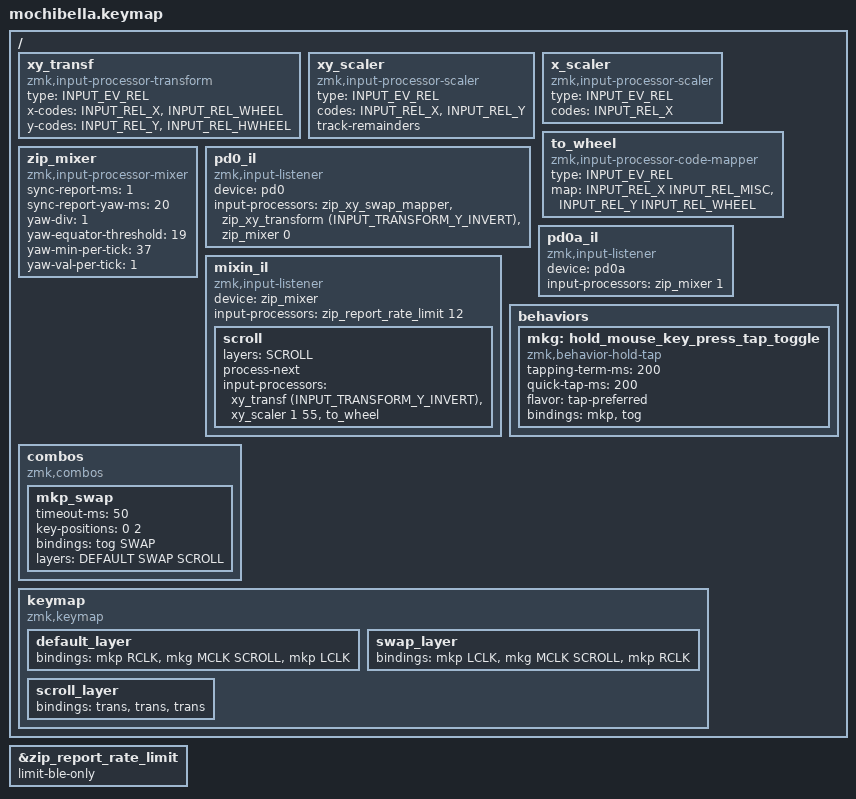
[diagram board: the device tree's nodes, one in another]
/*
 * Copyright (c) 2020 The ZMK Contributors
 *
 * SPDX-License-Identifier: MIT
 */

#include <zephyr/dt-bindings/input/input-event-codes.h>

#include <behaviors.dtsi>
// #include <behaviors/mouse_keys.dtsi>
#include <behaviors/mouse_key_press.dtsi>
#include <behaviors/mouse_key_toggle.dtsi>
#include <dt-bindings/zmk/keys.h>
#include <dt-bindings/zmk/bt.h>
#include <dt-bindings/zmk/outputs.h>
#include <dt-bindings/zmk/mouse.h>
#include <dt-bindings/zmk/input_transform.h>
#include <input/processors.dtsi>
#include <input/processors/report_rate_limit.dtsi>

#define DEFAULT 0
#define SWAP    1
#define SCROLL  2

&zip_report_rate_limit {
        limit-ble-only;
};

/ {
        xy_transf: xy_transf {
                compatible = "zmk,input-processor-transform";
                #input-processor-cells = <1>;
                type = <INPUT_EV_REL>;
                x-codes = <INPUT_REL_X>, <INPUT_REL_WHEEL>;
                y-codes = <INPUT_REL_Y>, <INPUT_REL_HWHEEL>;
        };
        xy_scaler: xy_scaler {
                compatible = "zmk,input-processor-scaler";
                #input-processor-cells = <2>;
                type = <INPUT_EV_REL>;
                codes = <INPUT_REL_X>, <INPUT_REL_Y>;
                track-remainders;
        };
        x_scaler: x_scaler {
                compatible = "zmk,input-processor-scaler";
                #input-processor-cells = <2>;
                type = <INPUT_EV_REL>;
                codes = <INPUT_REL_X>;
        };
        to_wheel: to_wheel {
                compatible = "zmk,input-processor-code-mapper";
                #input-processor-cells = <0>;
                type = <INPUT_EV_REL>;
                map = <INPUT_REL_X INPUT_REL_MISC>, <INPUT_REL_Y INPUT_REL_WHEEL>;
        };

        zip_mixer: zip_mixer {
                compatible = "zmk,input-processor-mixer";
                #input-processor-cells = <1>;
                sync-report-ms = <1>;
                sync-report-yaw-ms = <20>;
                yaw-div = <1>;
                yaw-equator-threshold = <19>;
                yaw-min-per-tick = <37>;
                yaw-val-per-tick = <1>;
	};

        pd0_il {
                compatible = "zmk,input-listener";
                device = <&pd0>;
                // sensor at 6 o'clock pos
                input-processors = <&zip_xy_swap_mapper>
                                , <&zip_xy_transform (INPUT_TRANSFORM_Y_INVERT)>
                                , <&zip_mixer 0>;
        };

        pd0a_il {
                compatible = "zmk,input-listener";
                device = <&pd0a>;
                // sensor at 3 o'clock pos
                input-processors = <&zip_mixer 1>;
        };

        mixin_il {
                compatible = "zmk,input-listener";
                device = <&zip_mixer>;
                input-processors = <&zip_report_rate_limit 12>;
                scroll {
                        layers = <SCROLL>;
                        process-next;
                        input-processors = <&xy_transf (INPUT_TRANSFORM_Y_INVERT)>
                                        , <&xy_scaler 1 55> // , <&x_scaler 0 1>
                                        , <&to_wheel>;
                };
        };

        behaviors {
                mkg: hold_mouse_key_press_tap_toggle {
                        compatible = "zmk,behavior-hold-tap"; #binding-cells = <2>;
                        tapping-term-ms = <200>; quick-tap-ms = <200>;
                        flavor = "tap-preferred"; bindings = <&mkp>, <&tog>;
                };
        };

        // button position view form top 
        //
        //     1
        //  0     2
        //
        combos {
                compatible = "zmk,combos";

                mkp_swap  {
                        timeout-ms = <50>;
                        key-positions = <0 2>;
                        bindings = <&tog SWAP>;
                        layers = <DEFAULT SWAP SCROLL>;
                };
        };

        keymap {
                compatible = "zmk,keymap";
                default_layer {
                        bindings = < &mkp RCLK   &mkg MCLK SCROLL    &mkp LCLK >;
                };
                swap_layer {
                        bindings = < &mkp LCLK   &mkg MCLK SCROLL    &mkp RCLK >;
                };
                scroll_layer {
                        bindings = < &trans      &trans              &trans >;
                };
       };
};
